# APM32F465 register map
File version: 1.0
CPU: CM4 r1p0, little endian, no MPU, no FPU, 3 interrupt priority bits
Registers are 32-bit, read-write, reset 0x0 unless marked. A register's access mark holds for its fields unless they carry their own. Offsets are from the block's base; [hi:lo] are bit positions; {n}, {i} and the like mark numbered series.

## SPI1 — Serial peripheral interface
Base 0x40013000
Same registers: I2S2ext 0x40003400, SPI2 0x40003800, SPI3 0x40003C00, I2S3ext 0x40004000
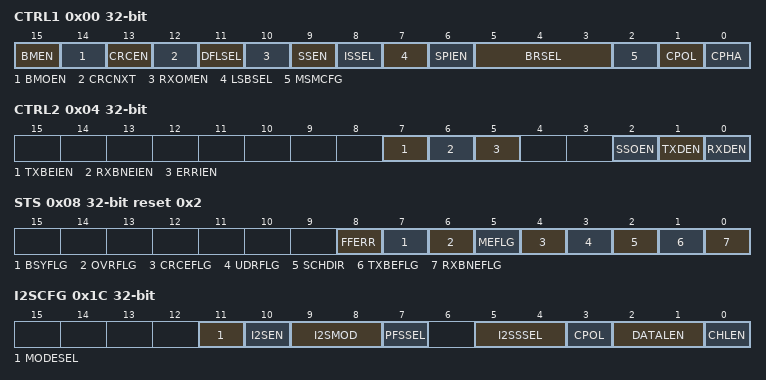
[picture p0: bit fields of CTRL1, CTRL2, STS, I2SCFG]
0x00 CTRL1 — control register 1
  [15] BMEN — Bidirectional data mode enable
  [14] BMOEN — Output enable in bidirectional mode
  [13] CRCEN — Hardware CRC calculation enable
  [12] CRCNXT — CRC transfer next
  [11] DFLSEL — Data frame format
  [10] RXOMEN — Receive only
  [9] SSEN — Software slave management
  [8] ISSEL — Internal slave select
  [7] LSBSEL — Frame format
  [6] SPIEN — SPI enable
  [5:3] BRSEL — Baud rate control
  [2] MSMCFG — Master selection
  [1] CPOL — Clock polarity
  [0] CPHA — Clock phase
0x04 CTRL2 — control register 2
  [7] TXBEIEN — Tx buffer empty interrupt enable
  [6] RXBNEIEN — RX buffer not empty interrupt enable
  [5] ERRIEN — Error interrupt enable
  [2] SSOEN — SS output enable
  [1] TXDEN — Tx buffer DMA enable
  [0] RXDEN — Rx buffer DMA enable
0x08 STS access per field reset 0x2 — status register
  [8] FFERR ro — TI frame format error
  [7] BSYFLG ro — Busy flag
  [6] OVRFLG ro — Overrun flag
  [5] MEFLG ro — Mode fault
  [4] CRCEFLG rw — CRC error flag
  [3] UDRFLG ro — Underrun flag
  [2] SCHDIR ro — Channel side
  [1] TXBEFLG ro — Transmit buffer empty
  [0] RXBNEFLG ro — Receive buffer not empty
0x0C DATA
  [15:0] DATA
0x10 CRCPOLY reset 0x7 — CRC polynomial register
  [15:0] CRCPOLY
0x14 RXCRC ro
  [15:0] RXCRC
0x18 TXCRC ro
  [15:0] TXCRC
0x1C I2SCFG — I2S configuration register
  [11] MODESEL — I2S mode selection
  [10] I2SEN — I2S Enable
  [9:8] I2SMOD — I2S configuration mode
  [7] PFSSEL — PCM frame synchronization
  [5:4] I2SSSEL — I2S standard selection
  [3] CPOL — Steady state clock polarity
  [2:1] DATALEN — Data length to be transferred
  [0] CHLEN — Channel length (number of bits per audio channel)
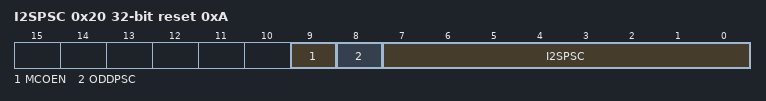
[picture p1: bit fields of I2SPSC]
0x20 I2SPSC reset 0xA — I2S prescaler register
  [9] MCOEN — Master clock output enable
  [8] ODDPSC — Odd factor for the prescaler
  [7:0] I2SPSC — I2S Linear prescaler

## DBGMCU — Debug support
Base 0xE0042000
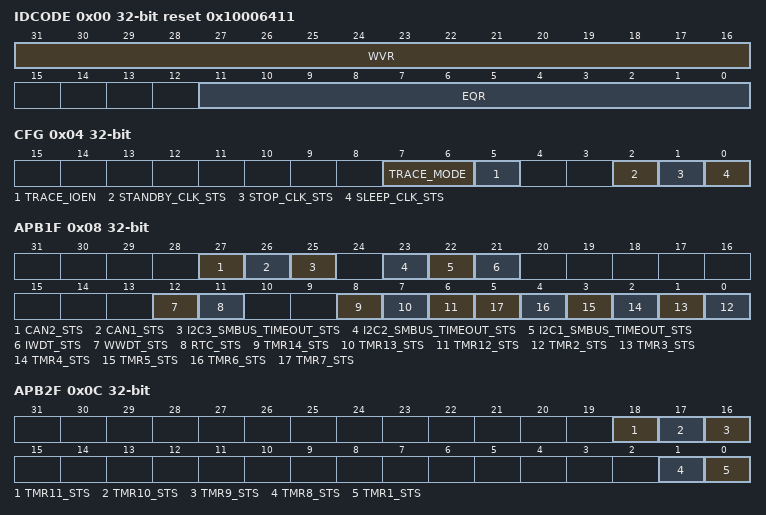
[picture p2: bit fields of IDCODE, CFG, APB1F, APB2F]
0x00 IDCODE ro reset 0x10006411
  [31:16] WVR — Wafer Version Recognition
  [11:0] EQR — Equipment Recognition
0x04 CFG — Control Register
  [7:6] TRACE_MODE — Trace Debug Pin Mode Configure
  [5] TRACE_IOEN — Trace Debug Pin Enable
  [2] STANDBY_CLK_STS — Configure clock status when MCU is debugged in standby mode
  [1] STOP_CLK_STS — Configure clock status when MCU is debugged in stop mode
  [0] SLEEP_CLK_STS — Configure clock status when MCU is debugged in sleep mode
0x08 APB1F — Debug MCU APB1 Freeze registe
  [27] CAN2_STS — CAN2 counter stopped when core is halted
  [26] CAN1_STS — CAN1 counter stopped when core is halted
  [25] I2C3_SMBUS_TIMEOUT_STS
  [23] I2C2_SMBUS_TIMEOUT_STS
  [22] I2C1_SMBUS_TIMEOUT_STS
  [21] IWDT_STS — IWDT counter stopped when core is halted
  [12] WWDT_STS — WWDT counter stopped when core is halted
  [11] RTC_STS — RTC counter stopped when core is halted
  [8] TMR14_STS — TMR14 counter stopped when core is halted
  [7] TMR13_STS — TMR13 counter stopped when core is halted
  [6] TMR12_STS — TMR12 counter stopped when core is halted
  [n-2] TMR{n}_STS (n=2..7) — TMR{n} counter stopped when core is halted
0x0C APB2F — Debug MCU APB2 Freeze registe
  [18] TMR11_STS — TMR11 counter stopped when core is halted
  [17] TMR10_STS — TMR10 counter stopped when core is halted
  [16] TMR9_STS — TMR9 counter stopped when core is halted
  [1] TMR8_STS — TMR8 counter stopped when core is halted
  [0] TMR1_STS — TMR1 counter stopped when core is halted

## SYSCFG — System configuration controller
Base 0x40013800
0x00 MMSEL — memory remap register
  [1:0] MMSEL — Memory Mapping Select
0x04 PMCFG — peripheral mode configuration register
  [23] ENETSEL — Ethernet PHY Interface Select
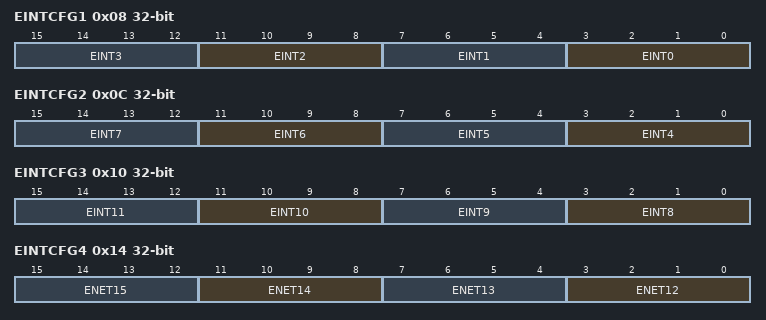
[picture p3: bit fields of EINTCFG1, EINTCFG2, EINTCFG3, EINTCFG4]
0x08 EINTCFG1 — external interrupt configuration register 1
  [4n+3:4n] EINT{n} (n=0..3) — EINTx Configure
0x0C EINTCFG2 — external interrupt configuration register 2
  [4n-13:4n-16] EINT{n} (n=4..7) — EINTx Configure
0x10 EINTCFG3 — external interrupt configuration register 3
  [4n-29:4n-32] EINT{n} (n=8..11) — EINTx Configure
0x14 EINTCFG4 — external interrupt configuration register 4
  [4n-45:4n-48] ENET{n} (n=12..15) — EINTx Configure
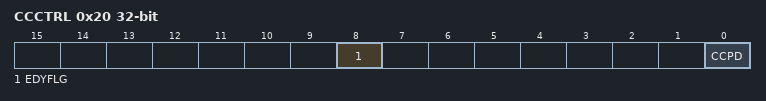
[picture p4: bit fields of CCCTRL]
0x20 CCCTRL access per field — Compensation cell control register
  [8] EDYFLG ro — Compensation Cell Ready Flag
  [0] CCPD rw — Compensation Cell Power-down
